# RSL15 register map
Vendor: ONSemiconductor; Series: RSL15 Series; File version: 1.0
CPU: CM33 r0p4, little endian, MPU, FPU, 3 interrupt priority bits
Registers are 32-bit, read-write, reset 0x0 unless marked. A register's access mark holds for its fields unless they carry their own. Offsets are from the block's base; [hi:lo] are bit positions; {n}, {i} and the like mark numbered series; <NAME> marks a mode.

## ACS
Base 0x40001B00
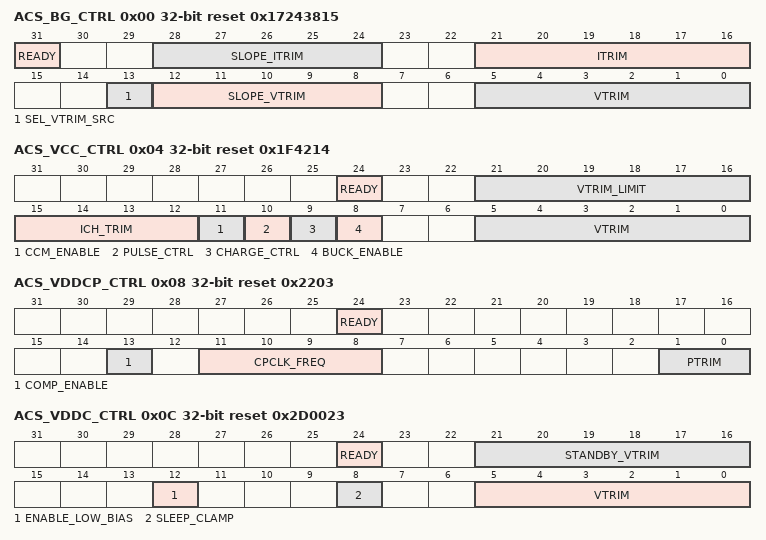
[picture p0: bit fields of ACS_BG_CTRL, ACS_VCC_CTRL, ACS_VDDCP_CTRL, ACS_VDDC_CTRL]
0x00 ACS_BG_CTRL reset 0x17243815 — Bandgap Control register
  [31] READY ro — Bandgap ready
    0=BG_NOT_READY (Bandgap reference not ready); 1=BG_READY (Bandgap reference ready)
  [28:24] SLOPE_ITRIM — Current temperature coefficient trimming
    23=BG_SLOPE_ITRIM_VALUE (Current temperature dependency 0 ppm/C)
  [21:16] ITRIM — Reference current trimming
    0=BG_ITRIM_0P64UA (0.64 uA); 1=BG_ITRIM_0P65UA (0.65 uA); 35=BG_ITRIM_0P99UA (0.99 uA); 36=BG_ITRIM_1P00UA (1.00 uA); 37=BG_ITRIM_1P01UA (1.01 uA); 62=BG_ITRIM_1P26UA (1.26 uA); 63=BG_ITRIM_1P27UA (1.27 uA)
  [13] SEL_VTRIM_SRC — Select trim source for SLOPE_VTRIM and VTRIM
    0=BG_VTRIM_SEL_REGISTER (Select register value); 1=BG_VTRIM_SEL_METAL (Select metal value)
  [12:8] SLOPE_VTRIM — Voltage temperature coefficient trimming
    24=BG_SLOPE_VTRIM_VALUE (Voltage temperature dependency 0 ppm/C)
  [5:0] VTRIM — Reference voltage trimming (5 mV steps)
    0=BG_VTRIM_MIN (bandgap voltage minimum trimming); 21=BG_VTRIM_DEFAULT (bandgap voltage default trimming); 63=BG_VTRIM_MAX (bandgap voltage maximum trimming)
0x04 ACS_VCC_CTRL reset 0x1F4214 — DC-DC / LDO Supply Configuration / Control register
  [24] READY ro — Supply ready (only makes sense in test mode)
    0=VCC_NOT_READY (Supply voltage not ready); 1=VCC_READY (Supply voltage ready)
  [21:16] VTRIM_LIMIT — Max VTRIM value that can be used. If VTRIM value is greater it will be limited to this value
    0=VCC_TRIM_LIMIT_1P00V (Output voltage limit 1.00V); 5=VCC_TRIM_LIMIT_1P05V (Output voltage limit 1.05V); 10=VCC_TRIM_LIMIT_1P10V (Output voltage limit 1.10V); 15=VCC_TRIM_LIMIT_1P15V (Output voltage limit 1.15V); 20=VCC_TRIM_LIMIT_1P20V (Output voltage limit 1.20V); 25=VCC_TRIM_LIMIT_1P25V (Output voltage limit 1.25V); 31=VCC_TRIM_LIMIT_1P31V (Output voltage limit 1.31V (This should be the max value allowed)); 35=VCC_TRIM_LIMIT_1P35V (Output voltage limit 1.35V (This is the max value allowed only during RF operation at max output power)); 63=VCC_TRIM_LIMIT_1P63V (Output voltage limit 1.63V)
  [15:12] ICH_TRIM — Inductor charge current trimming
    0=VCC_ICHTRIM_16MA (Charge pump max current to 16 mA); 1=VCC_ICHTRIM_32MA (Charge pump max current to 32 mA); 3=VCC_ICHTRIM_64MA (Charge pump max current to 64 mA); 4=VCC_ICHTRIM_80MA (Charge pump max current to 80 mA); 5=VCC_ICHTRIM_96MA (Charge pump max current to 96 mA); 15=VCC_ICHTRIM_256MA (Charge pump max current to 256 mA)
  [11] CCM_ENABLE — Enable CCM mode
    0=VCC_DCM_MODE (Discontinous current mode); 1=VCC_CCM_MODE (Continuous current mode enabled)
  [10] PULSE_CTRL — Pulse mode control
    0=VCC_SINGLE_PULSE (Single pulse per clock cycle); 1=VCC_MULTI_PULSE (Multi pulses enabled (until VCC > VCC_TRIM))
  [9] CHARGE_CTRL — Charge mode control
    0=VCC_CONSTANT_CHARGE (Constant charge transfer (valid for VBAT > VCC+0.2)); 1=VCC_CONSTANT_IMAX (Constant inductor maximum charge current)
  [8] BUCK_ENABLE — Enable buck converter mode
    0=VCC_LDO (Linear mode); 1=VCC_BUCK (Buck converter mode enabled)
  [5:0] VTRIM — Output voltage trimming configuration in 10 mV steps
    0=VCC_TRIM_1P00V (Output voltage 1.00V); 5=VCC_TRIM_1P05V (Output voltage 1.05V); 10=VCC_TRIM_1P10V (Output voltage 1.10V); 15=VCC_TRIM_1P15V (Output voltage 1.15V); 20=VCC_TRIM_1P20V (Output voltage 1.20V); 25=VCC_TRIM_1P25V (Output voltage 1.25V); 31=VCC_TRIM_1P31V (Output voltage 1.31V (This should be the max value allowed)); 35=VCC_TRIM_1P35V (Output voltage 1.35V (This is the absolute max value allowed, only for RF operation at max output power)); 63=VCC_TRIM_1P63V (Output voltage 1.63V)
0x08 ACS_VDDCP_CTRL reset 0x2203 — Charge Pump control register
  [24] READY ro — Supply ready
    0=VDDCP_NOT_READY (Charge pump voltage not ready); 1=VDDCP_READY (Charge pump voltage ready)
  [13] COMP_ENABLE — Force cp comparator enable
    0=VDDCP_COMP_AUTO (Comparator and resistive divider turned off when not required); 1=VDDCP_COMP_ENABLED (Comparator and resistive divider turned on (retro-compatible))
  [11:8] CPCLK_FREQ — Charge Pump clock frequency during power down modes
    0=VDDCP_CPCLK_32KHZ (CP clock = 32 kHz (WDG_SoC clock)); 1=VDDCP_CPCLK_16KHZ (CP clock = 16 kHz); 2=VDDCP_CPCLK_8KHZ (CP clock = 8 kHz); 3=VDDCP_CPCLK_4KHZ (CP clock = 4 kHz); 4=VDDCP_CPCLK_2KHZ (CP clock = 2 kHz); 5=VDDCP_CPCLK_1KHZ (CP clock = 1 kHz); 6=VDDCP_CPCLK_0P5KHZ (CP clock = 512 Hz); 7=VDDCP_CPCLK_0P25KHZ (CP clock = 256 Hz); 8=VDDCP_CPCLK_0P12KHZ (CP clock = 128 Hz)
  [1:0] PTRIM — Output power trimming
    0=VDDCP_PTRIM_4MA (CP max current to 4 mA); 1=VDDCP_PTRIM_8MA (CP max current to 8 mA); 2=VDDCP_PTRIM_12MA (CP max current to 12 mA); 3=VDDCP_PTRIM_16MA (CP max current to 16 mA)
0x0C ACS_VDDC_CTRL reset 0x2D0023 — Digital Core Voltage Regulator control register
  [24] READY ro — Supply ready
    0=VDDC_NOT_READY (Supply voltage not ready); 1=VDDC_READY (Supply voltage ready)
  [21:16] STANDBY_VTRIM — VDDC standby voltage trimming (10 mV steps)
    0=VDDC_STANDBY_TRIM_0P75V (0.75 V); 1=VDDC_STANDBY_TRIM_0P76V (0.76 V); 45=VDDC_STANDBY_TRIM_1P20V (1.2 V); 57=VDDC_STANDBY_TRIM_1P32V (1.32 V); 63=VDDC_STANDBY_TRIM_1P38V (1.38 V)
  [12] ENABLE_LOW_BIAS — Low power mode control
    0=VDDC_NOMINAL_BIAS (Nominal regulator biasing); 1=VDDC_LOW_BIAS (Low regulator biasing)
  [8] SLEEP_CLAMP — Sleep mode clamp control
    0=VDDC_SLEEP_HIZ (Set the output HIZ (floating) in sleep mode); 1=VDDC_SLEEP_GND (Clamp output to ground in sleep mode)
  [5:0] VTRIM — Output voltage trimming configuration in 10 mV steps
    0=VDDC_TRIM_0P75V (0.75 V); 1=VDDC_TRIM_0P76V (0.76 V); 25=VDDC_TRIM_1P00V (1.0 V); 33=VDDC_TRIM_1P08V (1.08 V); 35=VDDC_TRIM_1P10V (1.1 V); 45=VDDC_TRIM_1P20V (1.2 V); 50=VDDC_TRIM_1P25V (1.25 V); 57=VDDC_TRIM_1P32V (1.32 V); 63=VDDC_TRIM_1P38V (1.38 V)
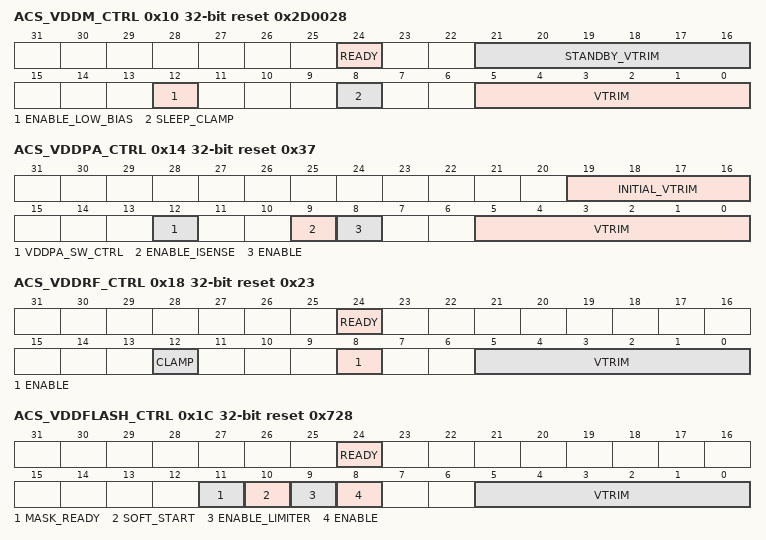
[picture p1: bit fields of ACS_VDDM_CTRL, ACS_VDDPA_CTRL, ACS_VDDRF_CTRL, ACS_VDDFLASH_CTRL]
0x10 ACS_VDDM_CTRL reset 0x2D0028 — Digital Core Voltage Regulator control register
  [24] READY ro — Supply ready
    0=VDDM_NOT_READY (Supply voltage not ready); 1=VDDM_READY (Supply voltage ready)
  [21:16] STANDBY_VTRIM — VDDM standby voltage trimming (10 mV steps)
    0=VDDM_STANDBY_TRIM_0P75V (0.75 V); 1=VDDM_STANDBY_TRIM_0P76V (0.76 V); 45=VDDM_STANDBY_TRIM_1P20V (1.2 V); 57=VDDM_STANDBY_TRIM_1P32V (1.32 V); 63=VDDM_STANDBY_TRIM_1P38V (1.38 V)
  [12] ENABLE_LOW_BIAS — Low power mode control
    0=VDDM_NOMINAL_BIAS (Nominal regulator biasing); 1=VDDM_LOW_BIAS (Low regulator biasing)
  [8] SLEEP_CLAMP — Sleep mode clamp control
    0=VDDM_SLEEP_HIZ (Set the output HIZ (floating) in sleep mode); 1=VDDM_SLEEP_GND (Clamp output to ground in sleep mode)
  [5:0] VTRIM — Output voltage trimming configuration in 10 mV steps
    0=VDDM_TRIM_0P75V (0.75 V); 1=VDDM_TRIM_0P76V (0.76 V); 25=VDDM_TRIM_1P00V (1.0 V); 33=VDDM_TRIM_1P08V (1.08 V); 35=VDDM_TRIM_1P10V (1.1 V); 40=VDDM_TRIM_1P15V (1.15 V); 45=VDDM_TRIM_1P20V (1.2 V); 50=VDDM_TRIM_1P25V (1.25 V); 57=VDDM_TRIM_1P32V (1.32 V); 63=VDDM_TRIM_1P38V (1.38 V)
0x14 ACS_VDDPA_CTRL reset 0x37 — RF Block Regulator Configuration / Control register
  [19:16] INITIAL_VTRIM — Initial output voltage trimming configuration in 10 mV steps
    0=VDDPA_INITIAL_TRIM_1P05V (1.05 V); 5=VDDPA_INITIAL_TRIM_1P10V (1.10 V); 15=VDDPA_INITIAL_TRIM_1P20V (1.20 V)
  [12] VDDPA_SW_CTRL — Power amplifier supply control
    0=VDDPA_SW_HIZ (Set the output HIZ (floating) in disable mode); 1=VDDPA_SW_VDDRF (Connect switched output to VDDRF regulator (ENABLE bit must be reset))
  [9] ENABLE_ISENSE — Enable current sensing circuit
    0=VDDPA_ISENSE_DISABLE (Disable the VDDPA regulator current sensing circuit); 1=VDDPA_ISENSE_ENABLE (Enable the VDDPA regulator current sensing circuit)
  [8] ENABLE — Enable control
    0=VDDPA_DISABLE (Disable the VDDPA regulator); 1=VDDPA_ENABLE (Enable the VDDPA regulator)
  [5:0] VTRIM — Output voltage trimming configuration in 10 mV steps
    0=VDDPA_TRIM_1P05V (1.05 V); 1=VDDPA_TRIM_1P06V (1.06 V); 54=VDDPA_TRIM_1P59V (1.59 V); 55=VDDPA_TRIM_1P60V (1.60 V); 56=VDDPA_TRIM_1P61V (1.61 V); 63=VDDPA_TRIM_1P68V (1.68 V)
0x18 ACS_VDDRF_CTRL reset 0x23 — RF Regulator control register
  [24] READY ro — Supply ready
    0=VDDRF_NOT_READY (Supply voltage not ready); 1=VDDRF_READY (Supply voltage ready)
  [12] CLAMP — Disable mode clamp control
    0=VDDRF_DISABLE_HIZ (Set the output HIZ (floating) in disable mode); 1=VDDRF_DISABLE_GND (Clamp output to ground in disable mode)
  [8] ENABLE — Enable control
    0=VDDRF_DISABLE (Disable the VDDRF regulator); 1=VDDRF_ENABLE (Enable the VDDRF regulator)
  [5:0] VTRIM — Output voltage trimming configuration in 10 mV steps
    0=VDDRF_TRIM_0P75V (0.75 V); 1=VDDRF_TRIM_0P76V (0.76 V); 25=VDDRF_TRIM_1P00V (1.0 V); 33=VDDRF_TRIM_1P08V (1.08 V); 35=VDDRF_TRIM_1P10V (1.1 V); 45=VDDRF_TRIM_1P20V (1.2 V); 57=VDDRF_TRIM_1P32V (1.32 V); 63=VDDRF_TRIM_1P38V (1.38 V)
0x1C ACS_VDDFLASH_CTRL reset 0x728 — VDDFLASH Block Regulator Configuration / Control register
  [24] READY ro — Supply ready
    0=VDDFLASH_NOT_READY (Supply voltage not ready); 1=VDDFLASH_READY (Supply voltage ready)
  [11] MASK_READY — Apply a mask to reset logic to ignore VDDFLASH ready signal
    0=VDDFLASH_USE_READY (Reset logic use VDDFLASH ready); 1=VDDFLASH_MASK_READY (Reset ignore VDDFLASH ready)
  [10] SOFT_START — Current limiter threshold setting
    0=VDDFLASH_LIMITER_70MA (Limiter current threshold at 70mA); 1=VDDFLASH_LIMITER_4MA (Limiter current threshold at 4mA)
  [9] ENABLE_LIMITER — Enable current limiter circuit
    0=VDDFLASH_LIMITER_DISABLE (Disable the VDDFLASH regulator current limiter circuit); 1=VDDFLASH_LIMITER_ENABLE (Enable the VDDFLASH regulator current limiter circuit)
  [8] ENABLE — Enable control
    0=VDDFLASH_DISABLE (Disable the VDDFLASH regulator); 1=VDDFLASH_ENABLE (Enable the VDDFLASH regulator)
  [5:0] VTRIM — Output voltage trimming configuration in 25 mV steps
    0=VDDFLASH_TRIM_0P750V (0.750V); 1=VDDFLASH_TRIM_0P775V (0.775V); 39=VDDFLASH_TRIM_1P725V (1.725V); 40=VDDFLASH_TRIM_1P750V (1.750V); 41=VDDFLASH_TRIM_1P775V (1.775V); 62=VDDFLASH_TRIM_2P300V (2.300V); 63=VDDFLASH_TRIM_2P325V (2.325V)
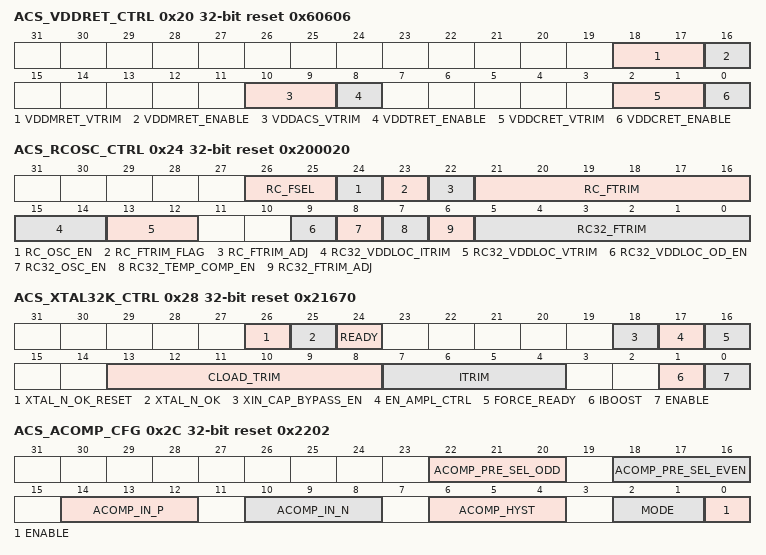
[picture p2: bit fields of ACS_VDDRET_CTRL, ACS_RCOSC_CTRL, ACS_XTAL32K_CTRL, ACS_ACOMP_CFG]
0x20 ACS_VDDRET_CTRL reset 0x60606 — Retention Regulator control register
  [18:17] VDDMRET_VTRIM — VDDMRET retention regulator voltage trimming
    3=VDDMRET_TRIM_VALUE (VDDMRET trimming value)
  [16] VDDMRET_ENABLE — Enable/Disable the VDDMRET retention regulator
    0=VDDMRET_DISABLE (The VDDMRET retention regulator is disabled); 1=VDDMRET_ENABLE (The VDDMRET retention regulator is enabled)
  [10:9] VDDACS_VTRIM — VDDACS regulator voltage trimming
    3=VDDACS_TRIM_VALUE (VDDACS trimming value)
  [8] VDDTRET_ENABLE — Enables the VDDT retention power (activate switch from VDDACS)
    0=VDDTRET_DISABLE (Disable BB timer retention supply (VDDT)); 1=VDDTRET_ENABLE (Enable BB timer retention supply (VDDT))
  [2:1] VDDCRET_VTRIM — VDDCRET Retention regulator voltage trimming
    3=VDDCRET_TRIM_VALUE (VDDCRET trimming value)
  [0] VDDCRET_ENABLE — Enables the VDDCRET Retention regulator
    0=VDDCRET_DISABLE (The VDDCRET retention regulator is disabled); 1=VDDCRET_ENABLE (The VDDCRET retention regulator is enabled)
0x24 ACS_RCOSC_CTRL reset 0x200020 — RC Oscillator control register
  [26:25] RC_FSEL — Select RC oscillator frequency
    0=RC_OSC_3MHZ (The RC Oscillator is at 3 MHz); 1=RC_OSC_12MHZ (The RC Oscillator is at 12 MHz); 2=RC_OSC_24MHZ (The RC Oscillator is at 24 MHz)
  [24] RC_OSC_EN — Enable/Disable the RC Oscillator
    0=RC_OSC_AUTO (The RC Oscillator is in auto mode); 1=RC_OSC_ENABLE (The RC Oscillator is enabled)
  [23] RC_FTRIM_FLAG — RC Oscillator Trimming flag
    0=RC_OSC_UNCALIBRATED (The oscillators are not calibrated); 1=RC_OSC_CALIBRATED (The oscillators are calibrated)
  [22] RC_FTRIM_ADJ — Adjust RC oscillator frequency range
    0=RC_OSC_RANGE_NOM (The RC Oscillator frequency range is nominal); 1=RC_OSC_RANGE_M15 (The RC Osc higher trim freq is decreased by 15 percent)
  [21:16] RC_FTRIM — RC oscillator frequency trimming
    0=RC_OSC_M48 (-48 percent trimming); 1=RC_OSC_M46P5 (-46.5 percent trimming); 32=RC_OSC_NOM (Nominal frequency); 63=RC_OSC_P46P5 (+46.5 percent trimming)
  [15:14] RC32_VDDLOC_ITRIM — VDDLOC current trimming
  [13:12] RC32_VDDLOC_VTRIM — VDDLOC voltage trimming
  [9] RC32_VDDLOC_OD_EN — Enable the overdrive of vddloc with VBAT
    0=RC32_OSC_VDDLOC_OD_DISABLE; 1=RC32_OSC_VDDLOC_OD_ENABLE
  [8] RC32_OSC_EN — Enable/Disable the 32 kHz RC Oscillator
    0=RC32_OSC_DISABLE (The 32kHz RC Oscillator is disabled); 1=RC32_OSC_ENABLE (The 32kHz RC Oscillator is enabled)
  [7] RC32_TEMP_COMP_EN — Enable/Disable the 32 kHz RC Oscillator
    0=RC32_TEMP_COMP_DISABLE (The 32kHz RC Oscillator temperature compensation is disabled); 1=RC32_TEMP_COMP_ENABLE (The 32kHz RC Oscillator temperature compensation is enabled)
  [6] RC32_FTRIM_ADJ — Adjust 32 kHz RC oscillator frequency range
    0=RC32_OSC_RANGE_NOM (The 32 kHz RC Oscillator frequency range is nominal); 1=RC32_OSC_RANGE_M25 (The 32 kHz RC Oscillator frequency range is lowered by 25 percent)
  [5:0] RC32_FTRIM — 32 kHz RC oscillator frequency trimming
    0=RC32_OSC_M48 (-48 percent trimming); 1=RC32_OSC_M46P5 (-46.5 percent trimming); 32=RC32_OSC_NOM (Nominal frequency); 63=RC32_OSC_P46P5 (+46.5 percent trimming)
0x28 ACS_XTAL32K_CTRL reset 0x21670 (reset mask 0x3073FF3) — Xtal 32 kHz configuration register
  [26] XTAL_N_OK_RESET wo — Reset Xtal not ok sticky flag
    1=XTAL32K_NOT_OK_RESET (Xtal 32K not reset)
  [25] XTAL_N_OK ro — Xtal not ready sticky flag
    0=XTAL_OK (Xtal 32K NOT OK sticky flag was not set); 1=XTAL_N_OK (Xtal 32K NOT OK sticky flag was set)
  [24] READY ro — Xtal ready status
    0=XTAL32K_NOT_OK (Xtal 32K not available); 1=XTAL32K_OK (Xtal 32K is OK)
  [18] XIN_CAP_BYPASS_EN — Switch to bypass the added XIN serial cap to reduce the leakage
    0=XTAL32K_XIN_CAP_BYPASS_DISABLE (Disable the Xtal bypass switch of the XIN serial cap); 1=XTAL32K_XIN_CAP_BYPASS_ENABLE (Enable the Xtal bypass switch of the XIN serial cap)
  [17] EN_AMPL_CTRL — Xtal enable amplitude control (regulation)
    0=XTAL32K_AMPL_CTRL_DISABLE (Xtal 32K amplitude control disabled); 1=XTAL32K_AMPL_CTRL_ENABLE (Xtal 32K amplitude control enabled)
  [16] FORCE_READY — Xtal bypass the ready detector
    0=XTAL32K_NOT_FORCE_READY (Xtal 32K ready not forced); 1=XTAL32K_FORCE_READY (Xtal 32K ready forced)
  [13:8] CLOAD_TRIM — Xtal load capacitance configuration
    0=XTAL32K_CTRIM_0P0PF (0 pF internal capacitor); 1=XTAL32K_CTRIM_0P4PF (0.4 pF internal capacitor); 22=XTAL32K_CTRIM_8P8PF (8.8 pF internal capacitor); 63=XTAL32K_CTRIM_25P2PF (25.2 pF internal capacitor)
  [7:4] ITRIM — Xtal current trimming
    0=XTAL32K_ITRIM_20NA (20 nA startup current); 3=XTAL32K_ITRIM_80NA (80 nA startup current); 7=XTAL32K_ITRIM_160NA (160 nA startup current); 15=XTAL32K_ITRIM_320NA (320 nA startup current)
  [1] IBOOST — Xtal current boosting (4x)
    0=XTAL32K_IBOOST_DISABLE (Disable the Xtal 32 kHz current boosting mode); 1=XTAL32K_IBOOST_ENABLE (Disable the Xtal 32 kHz enable boosting mode (4x itrim currents))
  [0] ENABLE — Enable the Xtal 32 kHz oscillator
    0=XTAL32K_DISABLE (Disable the Xtal 32 kHz oscillator); 1=XTAL32K_ENABLE (Enable the Xtal 32 kHz oscillator)
0x2C ACS_ACOMP_CFG reset 0x2202 — ACOMP configuration register
  [22:20] ACOMP_PRE_SEL_ODD — Pre selection of odd GPIOs
    0=ACOMP_PRE_SEL_GPIO_1 (Select GPIO[1] for "pre_sel_odd"); 1=ACOMP_PRE_SEL_GPIO_3 (Select GPIO[3] for "pre_sel_odd"); 2=ACOMP_PRE_SEL_GPIO_5 (Select GPIO[5] for "pre_sel_odd"); 3=ACOMP_PRE_SEL_GPIO_7 (Select GPIO[7] for "pre_sel_odd"); 4=ACOMP_PRE_SEL_GPIO_9 (Select GPIO[9] for "pre_sel_odd"); 5=ACOMP_PRE_SEL_GPIO_11 (Select GPIO[11] for "pre_sel_odd"); 6=ACOMP_PRE_SEL_GPIO_13 (Select GPIO[13] for "pre_sel_odd"); 7=ACOMP_PRE_SEL_GPIO_15 (Select GPIO[15] for "pre_sel_odd")
  [18:16] ACOMP_PRE_SEL_EVEN — Pre selection of even GPIOs
    0=ACOMP_PRE_SEL_GPIO_0 (Select GPIO[0] for "pre_sel_even"); 1=ACOMP_PRE_SEL_GPIO_2 (Select GPIO[2] for "pre_sel_even"); 2=ACOMP_PRE_SEL_GPIO_4 (Select GPIO[4] for "pre_sel_even"); 3=ACOMP_PRE_SEL_GPIO_6 (Select GPIO[6] for "pre_sel_even"); 4=ACOMP_PRE_SEL_GPIO_8 (Select GPIO[8] for "pre_sel_even"); 5=ACOMP_PRE_SEL_GPIO_10 (Select GPIO[10] for "pre_sel_even"); 6=ACOMP_PRE_SEL_GPIO_12 (Select GPIO[12] for "pre_sel_even"); 7=ACOMP_PRE_SEL_GPIO_14 (Select GPIO[14] for "pre_sel_even")
  [14:12] ACOMP_IN_P — Defines the positive input signal
    0=ACOMP_IN_P_SRC_PRE_SEL_EVEN (Select "pre_sel_even" as source); 1=ACOMP_IN_P_SRC_PRE_SEL_ODD (Select "pre_sel_odd" as source); 2=ACOMP_IN_P_SRC_VSSA (Select VSSA as source); 3=ACOMP_IN_P_SRC_WEDAC (Select WEDAC as source); 4=ACOMP_IN_P_SRC_PMU_VREF (Select PMU Vref as source); 5=ACOMP_IN_P_SRC_VBAT (Select VBAT as source); 6=ACOMP_IN_P_SRC_NOT_CONNECTED (Not connect the source)
  [10:8] ACOMP_IN_N — Defines the negative input signal
    0=ACOMP_IN_N_SRC_PRE_SEL_EVEN (Select "pre_sel_even" as source); 1=ACOMP_IN_N_SRC_PRE_SEL_ODD (Select "pre_sel_odd" as source); 2=ACOMP_IN_N_SRC_VSSA (Select VSSA as source); 3=ACOMP_IN_N_SRC_WEDAC (Select WEDAC as source); 4=ACOMP_IN_N_SRC_PMU_VREF (Select PMU Vref as source); 5=ACOMP_IN_N_SRC_VBAT (Select VBAT as source); 6=ACOMP_IN_N_SRC_NOT_CONNECTED (Not connect the source)
  [6:4] ACOMP_HYST — Hysteresis level
    0=HYST_0 (No hysteresis); 1=HYST_10MV (10 mV hysteresis); 2=HYST_20MV (20 mV hysteresis); 3=HYST_30MV (30 mV hysteresis); 4=HYST_40MV (40 mV hysteresis); 5=HYST_50MV (50 mV hysteresis); 6=HYST_60MV (60 mV hysteresis); 7=HYST_70MV (70 mV hysteresis)
  [2:1] MODE — Power mode selection
    0=ACOMP_LOW_POWER_MODE (Low power mode); 1=ACOMP_NORMAL_MODE (Normal mode); 2=ACOMP_HIGH_SPEED_MODE (High Speed mode)
  [0] ENABLE — Enable signal
    0=ACOMP_DIS (ACOMP disabled); 1=ACOMP_EN (ACOMP enabled)
0x30 ACS_ACOMP_OUT ro — ACOMP out
  [0] ACOMP_OUT — Comparison result
    0=Vinn > Vinp; 1=Vinn < Vinp
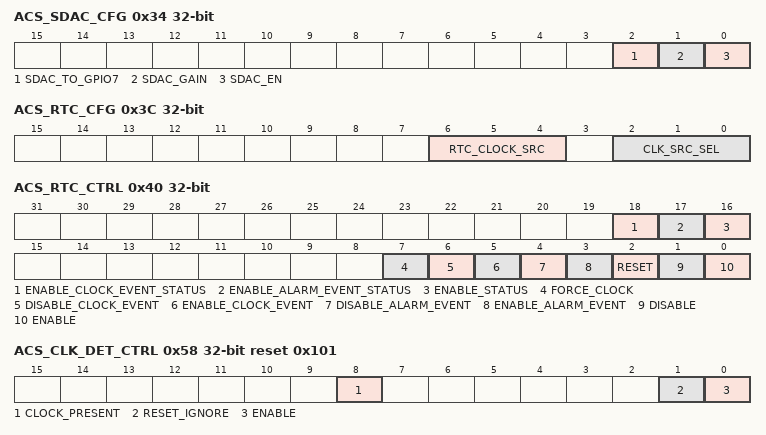
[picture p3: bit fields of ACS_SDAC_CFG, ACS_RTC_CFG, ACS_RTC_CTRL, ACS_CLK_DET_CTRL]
0x34 ACS_SDAC_CFG — SDAC configuration register
  [2] SDAC_TO_GPIO7 — GPIO7 drive by SDAC
    0=GPIO7_NOT_DRIVE_BY_SDAC (GPIO[7] not driven by SDAC); 1=GPIO7_DRIVE_BY_SDAC (GPIO[7] drives by SDAC)
  [1] SDAC_GAIN — Sets the SDAC buffer gain
    0=SDAC_GAIN_X1 (Gain = 1); 1=SDAC_GAIN_X2 (Gain = 2)
  [0] SDAC_EN — Enable signal for SDAC buffer
    0=SDAC_DISABLE (SDAC disabled); 1=SDAC_ENABLE (SDAC enabled)
0x38 ACS_WEDAC_CTRL reset 0x26 — WEDAC Control register
  [5:0] WEDAC — WEDAC setting
    0=WEDAC_0P000V (WEDAC = 0.000V); 1=WEDAC_0P016V (WEDAC = 0.016V); 2=WEDAC_0P032V (WEDAC = 0.032V); 31=WEDAC_0P496V (WEDAC = 0.496V); 32=WEDAC_0P504V (WEDAC = 0.504V); 38=WEDAC_0P600V (WEDAC = 0.600V); 39=WEDAC_0P616V (WEDAC = 0.616V); 62=WEDAC_0P984V (WEDAC = 0.984V); 63=WEDAC_1P000V (WEDAC = 1.000V)
0x3C ACS_RTC_CFG — RTC Configuration Register
  [6:4] RTC_CLOCK_SRC — Select the RTC Clock event source
    0=RTC_CLOCK_62MS (RTC clock on counter bit 10 rising edge (62 ms)); 1=RTC_CLOCK_125MS (RTC clock on counter bit 11 rising edge (125 ms)); 2=RTC_CLOCK_250MS (RTC clock on counter bit 12 rising edge (250 ms)); 3=RTC_CLOCK_500MS (RTC clock on counter bit 13 rising edge (500 ms)); 4=RTC_CLOCK_1S (RTC clock on counter bit 14 rising edge (1 s)); 5=RTC_CLOCK_2S (RTC clock on counter bit 15 rising edge (2 s)); 6=RTC_CLOCK_4S (RTC clock on counter bit 16 rising edge (4 s)); 7=RTC_CLOCK_8S (RTC clock on counter bit 17 rising edge (8 s))
  [2:0] CLK_SRC_SEL — Select the RTC, standby, bb timer, and sensor block clock source
    0=RTC_CLK_SRC_STANDBY_CLK (Select standby clock that runs at 32kHz as clock source); {v}=RTC_CLK_SRC_GPIO{v-1} (Select GPIO[{v-1}] as clock source) (v=1..4); 5=RTC_CLK_SRC_NO_CLOCK (Set RTC clock to constant value 0)
0x40 ACS_RTC_CTRL (reset mask 0x70000) — RTC Control Register
  [18] ENABLE_CLOCK_EVENT_STATUS ro — Status of the RTC clock event enable
    0=RTC_CLOCK_EVENT_IS_DISABLED (The RTC clock event is disabled); 1=RTC_CLOCK_EVENT_IS_ENABLED (The RTC clock event is enabled)
  [17] ENABLE_ALARM_EVENT_STATUS ro — Status of the RTC alarm event enable
    0=RTC_ALARM_EVENT_IS_DISABLED (The RTC alarm event is disabled); 1=RTC_ALARM_EVENT_IS_ENABLED (The RTC alarm event is enabled)
  [16] ENABLE_STATUS ro — Status of the RTC enable
    0=RTC_IS_DISABLED (The RTC is disabled); 1=RTC_IS_ENABLED (The RTC is enabled)
  [7] FORCE_CLOCK wo — Force a clock on RTC timer (Test Purpose)
    1=RTC_FORCE_CLOCK (Clock the RTC timer (has an effect only if the source clock is low))
  [6] DISABLE_CLOCK_EVENT wo — Disable clock event and its interrupt
    1=RTC_DISABLE_CLOCK_EVENT (Disable RTC clock event)
  [5] ENABLE_CLOCK_EVENT wo — Enable clock event and its interrupt
    1=RTC_ENABLE_CLOCK_EVENT (Enable RTC clock event)
  [4] DISABLE_ALARM_EVENT wo — Disable alarm event and its interrupt
    1=RTC_DISABLE_ALARM_EVENT (Disable RTC alarm event)
  [3] ENABLE_ALARM_EVENT wo — Enable alarm event and its interrupt
    1=RTC_ENABLE_ALARM_EVENT (Enable RTC alarm event)
  [2] RESET wo — Reset the RTC timer
    1=RTC_RESET (The RTC counters are reset (prescale and counter))
  [1] DISABLE wo — Disable counter and RTC interrupt every 1s
    1=RTC_DISABLE (Disable RTC)
  [0] ENABLE wo — Enable counter and RTC interrupt every 1s
    1=RTC_ENABLE (Enable RTC)
0x44 ACS_RTC_COUNT_THRES reset 0xFFFFFFFF — RTC Counter Threshold
  [31:0] THRESHOLD — Compare value for the RTC counter
    0=RTC_COUNT_THRES_0 (Compare to 0); 1=RTC_COUNT_THRES_1 (Compare to 1); 0x7FFF=RTC_COUNT_THRES_32767 (Compare to 32,767); 0xFFFFFFFF=RTC_COUNT_THRES_4294967295 (Compare to 4,294,967,295)
0x48 ACS_RTC_COUNT ro — RTC Counter Current Value
  [31:0] VALUE — RTC timer current value
0x4C ACS_RTC_SECONDS ro — RTC Counter Current Value in seconds
  [16:0] VALUE — RTC timer current value in seconds
0x50 ACS_RTC_COUNT_LOAD reset not defined — Load RTC Counter Current Value
  [31:0] VALUE wo — Load the RTC timer current value
0x54 ACS_BB_TIMER_CTRL — Baseband timer and standby clock control register
  [0] BB_TIMER_NRESET — nReset signal for the baseband timer
    0=BB_TIMER_RESET (Baseband timer is in reset state); 1=BB_TIMER_NRESET (Baseband timer reset is released)
0x58 ACS_CLK_DET_CTRL reset 0x101 — Clock Detector Configuration register
  [8] CLOCK_PRESENT ro — Clock present flag
    0=ACS_CLK_DET_NO_CLOCK (No clock detected); 1=ACS_CLK_DET_CLOCK_PRESENT (Clock detected)
  [1] RESET_IGNORE — Clock detector reset condition ignore
    1=ACS_CLK_DET_RESET_DISABLE (Clock detector reset condition ignore); 0=ACS_CLK_DET_RESET_ENABLE (Clock detector reset condition accept)
  [0] ENABLE — Clock detector enable
    1=ACS_CLK_DET_ENABLE (Clock detector enable); 0=ACS_CLK_DET_DISABLE (Clock detector disable)
0x5C ACS_PWR_MODES_CTRL reset not defined — Power Modes Control Register
  [31:0] POWER_MODE wo — 32-bit key to enter STANDBY, SLEEP, or DEEP_SLEEP mode. This register must be written using a 32-bit access.
    0=PWR_RUN_MODE (Keep the system in normal RUN mode); 0x9B1D79A0=PWR_STANDBY_MODE (Enter STANDBY mode); 0xE0045650=PWR_SLEEP_MODE (Enter SLEEP mode); 0x53C02890=PWR_DEEP_SLEEP_MODE (Enter DEEP_SLEEP mode)
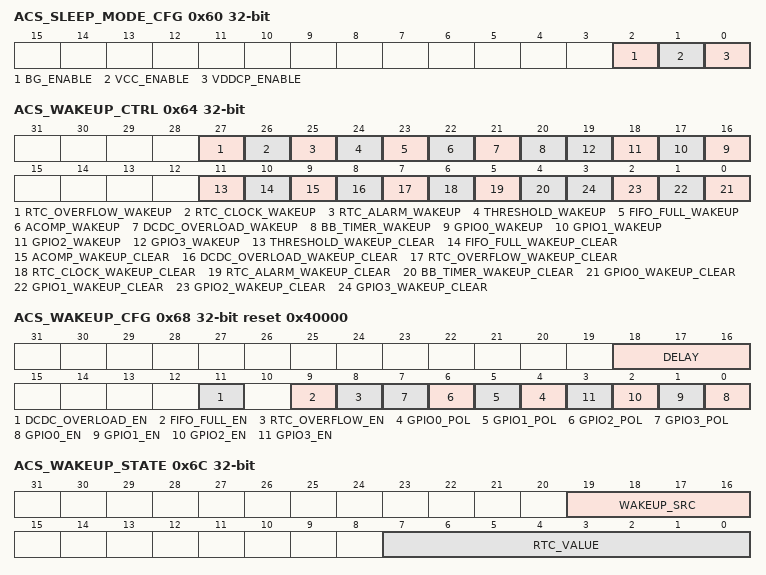
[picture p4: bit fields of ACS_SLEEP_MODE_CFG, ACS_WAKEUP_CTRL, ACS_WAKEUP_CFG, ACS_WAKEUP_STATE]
0x60 ACS_SLEEP_MODE_CFG — Sleep power mode configuration
  [2] BG_ENABLE — Keep Band-gap enabled during sleep
    0=BG_DISABLE_IN_SLEEP (Band-gap disabled in sleep); 1=BG_ENABLE_IN_SLEEP (Band-gap enabled in sleep)
  [1] VCC_ENABLE — Keep VCC low power enabled during sleep
    0=VCC_DISABLE_IN_SLEEP (VCC disabled in sleep); 1=VCC_ENABLE_IN_SLEEP (VCC enabled in sleep)
  [0] VDDCP_ENABLE — Keep VDDCP charge pump enabled during sleep
    0=VDDCP_DISABLE_IN_SLEEP (Charge pump disabled in sleep); 1=VDDCP_ENABLE_IN_SLEEP (Charge pump enabled in sleep)
0x64 ACS_WAKEUP_CTRL (reset mask 0xFFF0000) — Wake-Up control / Status Register
  [27] RTC_OVERFLOW_WAKEUP ro — Indicate if RTC overflow has triggered a wake-up event
    0=WAKEUP_RTC_OVERFLOW_EVENT_NOT_SET (RTC overflow has not triggered a wake-up event); 1=WAKEUP_RTC_OVERFLOW_EVENT_SET (RTC overflow has triggered a wake-up event at least once)
  [26] RTC_CLOCK_WAKEUP ro — Indicate if RTC clock has triggered a wake-up event
    0=WAKEUP_RTC_CLOCK_EVENT_NOT_SET (RTC clock has not triggered a wake-up event); 1=WAKEUP_RTC_CLOCK_EVENT_SET (RTC clock has triggered a wake-up event at least once)
  [25] RTC_ALARM_WAKEUP ro — Indicate if RTC alarm has triggered a wake-up event
    0=WAKEUP_RTC_ALARM_EVENT_NOT_SET (RTC alarm has not triggered a wake-up event); 1=WAKEUP_RTC_ALARM_EVENT_SET (RTC alarm has triggered a wake-up event at least once)
  [24] THRESHOLD_WAKEUP ro — Indicate if the sensor interface threshold has triggered a wake-up event
    0=WAKEUP_THRESHOLD_EVENT_NOT_SET (The ULP data acquisition subsystem threshold has not triggered a wake-up event); 1=WAKEUP_THRESHOLD_EVENT_SET (The ULP data acquisition subsystem threshold has triggered a wake-up event at least once)
  [23] FIFO_FULL_WAKEUP ro — Indicate if the sensor interface FIFO has triggered a wake-up event
    0=WAKEUP_FIFO_FULL_EVENT_NOT_SET (The ULP data acquisition subsystem FIFO has not triggered a wake-up event); 1=WAKEUP_FIFO_FULL_EVENT_SET (The ULP data acquisition subsystem FIFO has triggered a wake-up event at least once)
  [22] ACOMP_WAKEUP ro — Indicate if ACOMP has triggered a wake-up event
    0=WAKEUP_ACOMP_EVENT_NOT_SET (The ACOMP has not triggered a wake-up event); 1=WAKEUP_ACOMP_EVENT_SET (The ACOMP has triggered a wake-up event at least once)
  [21] DCDC_OVERLOAD_WAKEUP ro — Indicate if DCDC overload has triggered a wake-up event
    0=WAKEUP_DCDC_OVERLOAD_EVENT_NOT_SET (DCDC overload has not triggered a wake-up event); 1=WAKEUP_DCDC_OVERLOAD_EVENT_SET (DCDC overload has triggered a wake-up event at least once)
  [20] BB_TIMER_WAKEUP ro — Indicate if baseband timer has triggered a wake-up event
    0=WAKEUP_BB_TIMER_EVENT_NOT_SET (BB timer has not triggered a wake-up event); 1=WAKEUP_BB_TIMER_EVENT_SET (BB timer has triggered a wake-up event at least once)
  [n+16] GPIO{n}_WAKEUP ro (n=0..3) — Indicate if GPIO{n} has triggered a wake-up event
    0=WAKEUP_GPIO{n}_EVENT_NOT_SET (GPIO{n} has not triggered a wake-up event); 1=WAKEUP_GPIO{n}_EVENT_SET (GPIO{n} has triggered a wake-up event at least once)
  [11] THRESHOLD_WAKEUP_CLEAR wo — Reset the sticky WAKEUP_THRESHOLD_EVENT flag
    1=THRESHOLD_FULL_EVENT_CLEAR (Reset the sticky WAKEUP_THRESHOLD_EVENT flag)
  [10] FIFO_FULL_WAKEUP_CLEAR wo — Reset the sticky WAKEUP_FIFO_FULL_EVENT flag
    1=WAKEUP_FIFO_FULL_EVENT_CLEAR (Reset the sticky WAKEUP_FIFO_FULL_EVENT flag)
  [9] ACOMP_WAKEUP_CLEAR wo — Reset the sticky WAKEUP_ACOMP_EVENT flag
    1=WAKEUP_ACOMP_EVENT_CLEAR (Reset the sticky WAKEUP_ACOMP_EVENT flag)
  [8] DCDC_OVERLOAD_WAKEUP_CLEAR wo — Reset the sticky WAKEUP_DCDC_OVERLOAD flag
    1=WAKEUP_DCDC_OVERLOAD_EVENT_CLEAR (Reset the sticky WAKEUP_DCDC_OVERLOAD flag)
  [7] RTC_OVERFLOW_WAKEUP_CLEAR wo — Reset the sticky WAKEUP_RTC_OVERFLOW_EVENT flag
    1=WAKEUP_RTC_OVERFLOW_EVENT_CLEAR (Reset the sticky WAKEUP_RTC_OVERFLOW_EVENT flag)
  [6] RTC_CLOCK_WAKEUP_CLEAR wo — Reset the sticky WAKEUP_RTC_CLOCK_EVENT flag
    1=WAKEUP_RTC_CLOCK_EVENT_CLEAR (Reset the sticky WAKEUP_RTC_CLOCK_EVENT flag)
  [5] RTC_ALARM_WAKEUP_CLEAR wo — Reset the sticky WAKEUP_RTC_ALARM_EVENT flag
    1=WAKEUP_RTC_ALARM_EVENT_CLEAR (Reset the sticky WAKEUP_RTC_ALARM_EVENT flag)
  [4] BB_TIMER_WAKEUP_CLEAR wo — Reset the sticky WAKEUP_BB_TIMER_EVENT flag
    1=WAKEUP_BB_TIMER_CLEAR (Reset the sticky WAKEUP_BB_TIMER_EVENT flag)
  [n] GPIO{n}_WAKEUP_CLEAR wo (n=0..3) — Reset the sticky WAKEUP_GPIO{n}_EVENT flag
    1=WAKEUP_GPIO{n}_EVENT_CLEAR (Reset the sticky WAKEUP_GPIO{n}_EVENT flag)
0x68 ACS_WAKEUP_CFG reset 0x40000 — Wake-up Configuration Register
  [18:16] DELAY — Delay from VDDD ready to digital clock enable (power of 2)
    0=WAKEUP_DELAY_1 (Wait for 1 32kHz clock cycle); 1=WAKEUP_DELAY_2 (Wait for 2 32kHz clock cycles); 2=WAKEUP_DELAY_4 (Wait for 4 32kHz clock cycles); 3=WAKEUP_DELAY_8 (Wait for 8 32kHz clock cycles); 4=WAKEUP_DELAY_16 (Wait for 16 32kHz clock cycles); 5=WAKEUP_DELAY_32 (Wait for 32 32kHz clock cycles); 6=WAKEUP_DELAY_64 (Wait for 64 32kHz clock cycles); 7=WAKEUP_DELAY_128 (Wait for 128 32kHz clock cycles)
  [11] DCDC_OVERLOAD_EN — Enable / Disable the Wake-up functionality on the DCDC overload flag
    0=WAKEUP_DCDC_OVERLOAD_DISABLE (Disable the wake-up functionality on the DCDC overload flag); 1=WAKEUP_DCDC_OVERLOAD_ENABLE (Enable the wake-up functionality on the DCDC overload flag)
  [9] FIFO_FULL_EN — Enable the wake-up on full FIFO
    0=WAKEUP_FIFO_DISABLE (Disable the wake-up functionality on the ULP data acquisition subsystem FIFO); 1=WAKEUP_FIFO_ENABLE (Enable the wake-up functionality on the ULP data acquisition subsystem FIFO)
  [8] RTC_OVERFLOW_EN — Enable / Disable the Wake-up functionality on RTC overflow flag
    0=WAKEUP_RTC_OVERFLOW_DISABLE (Disable the wake-up functionality on the RTC overflow flag); 1=WAKEUP_RTC_OVERFLOW_ENABLE (Enable the wake-up functionality on the RTC overflow flag)
  [n+4] GPIO{n}_POL (n=0..3) — Wake-up polarity on the GPIO{n} pad
    0=WAKEUP_GPIO{n}_RISING (Wake-up on the GPIO{n} rising edge); 1=WAKEUP_GPIO{n}_FALLING (Wake-up on the GPIO{n} falling edge)
  [n] GPIO{n}_EN (n=0..3) — Enable the wake-up functionality on the GPIO{n} pad
    0=WAKEUP_GPIO{n}_DISABLE (Disable the wake-up functionality on the GPIO{n} pad); 1=WAKEUP_GPIO{n}_ENABLE (Enable the wake-up functionality on the GPIO{n} pad)
0x6C ACS_WAKEUP_STATE ro — RTC Timer wake-up value and wakeup source
  [19:16] WAKEUP_SRC — Status register indicates the last wake-up source
    11=WAKEUP_DUE_TO_RTC_OVERFLOW (The last wake-up was due to the RTC Timer overflow); 10=WAKEUP_DUE_TO_RTC_CLOCK (The last wake-up was due to the RTC Timer clock); 9=WAKEUP_DUE_TO_RTC_ALARM (The last wake-up was due to the RTC Timer alarm); 8=WAKEUP_DUE_TO_THRESHOLD (The last wake-up was due to the ULP data acquisition subsystem threshold); 7=WAKEUP_DUE_TO_FIFO (The last wake-up was due to the ULP data acquisition subsystem FIFO); 6=WAKEUP_DUE_TO_ACOMP (The last wake-up was due to the Analog comparator); 5=WAKEUP_DUE_TO_DCDC_OVERLOAD (The last wake-up was due to the DCDC overload); 4=WAKEUP_DUE_TO_BB_TIMER (The last wake-up was due to the baseband timer alarm); {v}=WAKEUP_DUE_TO_GPIO{v} (The last wake-up was due to the GPIO{v} pad) (v=0..3)
  [7:0] RTC_VALUE — RTC counter value captured at wakeup event (only 8 LSBs, corresponds to 7.8 ms)
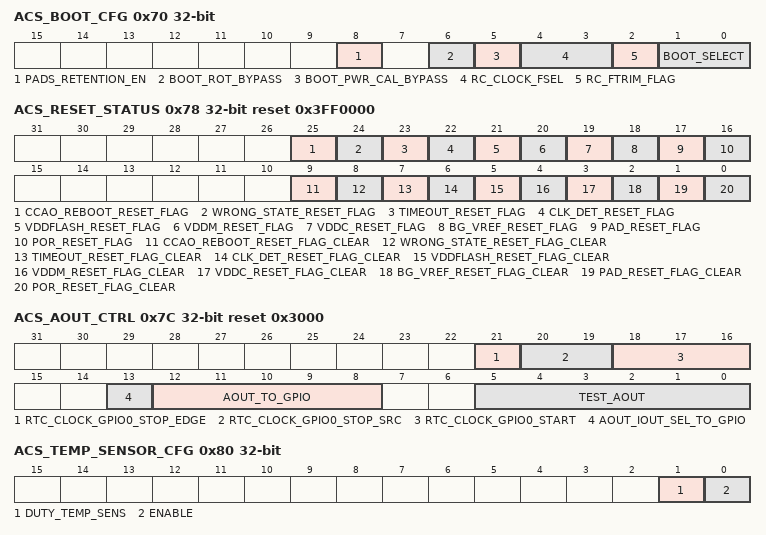
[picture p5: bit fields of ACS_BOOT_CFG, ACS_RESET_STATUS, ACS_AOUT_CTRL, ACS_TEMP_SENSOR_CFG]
0x70 ACS_BOOT_CFG — Boot configuration Register
  [8] PADS_RETENTION_EN — Enable / Disable the retention mode of the pads
    0=PADS_RETENTION_DISABLE (Disable the pad retention mode); 1=PADS_RETENTION_ENABLE (Enable the pad retention mode)
  [6] BOOT_ROT_BYPASS — Boot bypass execution of root of trust
    0=BOOT_ROT_BYPASS_DISABLE (ROM will execute RoT); 1=BOOT_ROT_BYPASS_ENABLE (ROM will not execute RoT)
  [5] BOOT_PWR_CAL_BYPASS — Boot bypass execution of system calibration
    0=BOOT_PWR_CAL_BYPASS_DISABLE (ROM will execute calibration of system); 1=BOOT_PWR_CAL_BYPASS_ENABLE (ROM will not execute calibration of system)
  [4:3] RC_CLOCK_FSEL ro — RC oscillator clock multiplier read only flag (mirror of CLOCK_MULT of ACS_RCOSC_CTRL register)
    0=RC_OSC_STATUS_3MHZ (The RC Oscillator is at 3 MHz); 1=RC_OSC_STATUS_12MHZ (The RC Oscillator is at 12 MHz); 2=RC_OSC_STATUS_24MHZ (The RC Oscillator is at 24 MHz); 3=RC_OSC_STATUS_48MHZ (The RC Oscillator is at 48 MHz)
  [2] RC_FTRIM_FLAG ro — RC oscillator trimming read only flag (mirror of FTRIM_FLAG of ACS_RCOSC_CTRL register
    0=RC_OSC_STATUS_UNCALIBRATED (The oscillators are not calibrated); 1=RC_OSC_STATUS_CALIBRATED (The oscillators are calibrated)
  [1:0] BOOT_SELECT — Boot selection to indicate boot source
    0=BOOT_FLASH_XTAL_DISABLE (The CM33 executes code from the flash and the XTAL will not be started at boot); 1=BOOT_CUSTOM (The CM33 executes code from the address specified in the wakeup information in retention RAM and the XTAL will not be started at boot); 2=BOOT_FLASH_XTAL_DEFAULT_TRIM (The CM33 executes code from the flash and the XTAL will be started at boot with the default trim); 3=BOOT_FLASH_XTAL_CUSTOM_TRIM (The CM33 executes code from the flash and the XTAL will be started at boot with trim from ACS_WAKEUP_GP_DATA)
0x74 ACS_BOOT_GP_DATA — Boot control Register Register
  [31:0] GP_DATA — 32-bit General-Purpose RW Data
0x78 ACS_RESET_STATUS reset 0x3FF0000 (reset mask 0x3FF0000) — ACS Reset Source Status Register
  [25] CCAO_REBOOT_RESET_FLAG ro — Sticky flag that detects that a CryptoCell Alway ON reboot reset occurred
    0=CCAO_REBOOT_RESET_FLAG_NOT_SET (The CryptoCell Always ON reboot reset has not triggered at least once); 1=CCAO_REBOOT_RESET_FLAG_SET (The CryptoCell Always ON reboot reset was triggered at least once since this status bit was last cleared)
  [24] WRONG_STATE_RESET_FLAG ro — Sticky flag that detects that a wrong state reset occurred
    0=WRONG_STATE_RESET_FLAG_NOT_SET (The wrong state reset has not triggered at least once); 1=WRONG_STATE_RESET_FLAG_SET (The wrong state reset was triggered at least once since this status bit was last cleared)
  [23] TIMEOUT_RESET_FLAG ro — Sticky flag that detects that a timeout in the power up sequence occurred
    0=TIMEOUT_RESET_FLAG_NOT_SET (The timeout reset has not triggered at least once); 1=TIMEOUT_RESET_FLAG_SET (The timeout reset was triggered at least once since this status bit was last cleared)
  [22] CLK_DET_RESET_FLAG ro — Sticky flag that detects that a clock detector reset occurred
    0=CLK_DET_RESET_FLAG_NOT_SET (The clock detector reset has not triggered at least once); 1=CLK_DET_RESET_FLAG_SET (The clock detector reset was triggered at least once since this status bit was last cleared)
  [21] VDDFLASH_RESET_FLAG ro — Sticky flag that detects that a VDDFLASH reset occurred (triggered by VDDFLASH_ready = 0)
    0=VDDFLASH_RESET_FLAG_NOT_SET (The VDDFLASH reset has not triggered at least once); 1=VDDFLASH_RESET_FLAG_SET (The VDDFLASH reset was triggered at least once since this status bit was last cleared)
  [20] VDDM_RESET_FLAG ro — Sticky flag that detects that a VDDM reset occurred (triggered by VDDM_ready = 0)
    0=VDDM_RESET_FLAG_NOT_SET (The VDDM reset has not triggered at least once); 1=VDDM_RESET_FLAG_SET (The VDDM reset was triggered at least once since this status bit was last cleared)
  [19] VDDC_RESET_FLAG ro — Sticky flag that detects that a VDDC reset occurred (triggered by VDDC_ready = 0)
    0=VDDC_RESET_FLAG_NOT_SET (The VDDC reset has not triggered at least once); 1=VDDC_RESET_FLAG_SET (The VDDC reset was triggered at least once since this status bit was last cleared)
  [18] BG_VREF_RESET_FLAG ro — Sticky flag that detects that a Bandagap reference voltage reset occurred
    0=BG_VREF_RESET_FLAG_NOT_SET (The band-gap reference voltage reset has not triggered at least once); 1=BG_VREF_RESET_FLAG_SET (The band-gap reference voltage was triggered at least once since this status bit was last cleared)
  [17] PAD_RESET_FLAG ro — Sticky flag that detects that a reset occurred due to pad NRESET
    0=PAD_RESET_FLAG_NOT_SET (The NRESET pad reset has not triggered at least once); 1=PAD_RESET_FLAG_SET (The NRESET pad reset was triggered at least once since this status bit was last cleared)
  [16] POR_RESET_FLAG ro — Sticky flag that detects that a POR reset occurred
    0=POR_RESET_FLAG_NOT_SET (The POR reset has not triggered at least once); 1=POR_RESET_FLAG_SET (The POR reset was triggered at least once since this status bit was last cleared)
  [9] CCAO_REBOOT_RESET_FLAG_CLEAR wo — Reset the sticky CCAO_REBOOT_RESET flag.
    1=CCAO_REBOOT_RESET_FLAG_CLEAR (Reset the sticky CCAO_REBOOT_RESET flag.)
  [8] WRONG_STATE_RESET_FLAG_CLEAR wo — Reset the sticky WRONG_STATE_RESET flag.
    1=WRONG_STATE_RESET_FLAG_CLEAR (Reset the sticky WRONG_STATE_RESET flag.)
  [7] TIMEOUT_RESET_FLAG_CLEAR wo — Reset the sticky TIMEOUT_RESET flag.
    1=TIMEOUT_RESET_FLAG_CLEAR (Reset the sticky TIMEOUT_RESET flag.)
  [6] CLK_DET_RESET_FLAG_CLEAR wo — Reset the sticky CLK_DET_RESET flag.
    1=CLK_DET_RESET_FLAG_CLEAR (Reset the sticky CLK_DET_RESET flag.)
  [5] VDDFLASH_RESET_FLAG_CLEAR wo — Reset the sticky VDDFLASH_RESET flag.
    1=VDDFLASH_RESET_FLAG_CLEAR (Reset the sticky VDDFLASH_RESET flag.)
  [4] VDDM_RESET_FLAG_CLEAR wo — Reset the sticky VDDM_RESET flag.
    1=VDDM_RESET_FLAG_CLEAR (Reset the sticky VDDM_RESET flag.)
  [3] VDDC_RESET_FLAG_CLEAR wo — Reset the sticky VDDC_RESET flag.
    1=VDDC_RESET_FLAG_CLEAR (Reset the sticky VDDC_RESET flag.)
  [2] BG_VREF_RESET_FLAG_CLEAR wo — Reset the sticky BG_VREF_RESET flag.
    1=BG_VREF_RESET_FLAG_CLEAR (Reset the sticky BG_VREF_RESET flag.)
  [1] PAD_RESET_FLAG_CLEAR wo — Reset the sticky PAD_RESET flag.
    1=PAD_RESET_FLAG_CLEAR (Reset the sticky PAD_RESET flag.)
  [0] POR_RESET_FLAG_CLEAR wo — Reset the sticky POR_RESET flag.
    1=POR_RESET_FLAG_CLEAR (Reset the sticky POR_RESET flag.)
0x7C ACS_AOUT_CTRL reset 0x3000 — Analog Output Configuration Register
  [21] RTC_CLOCK_GPIO0_STOP_EDGE — Stop edge for RTC clock output on AOUT
    0=GPIO0_RTC_CLK_STOP_RISING (Stop to output RTC clock on rising edge); 1=GPIO0_RTC_CLK_STOP_FALLING (Stop to output RTC clock on falling edge)
  [20:19] RTC_CLOCK_GPIO0_STOP_SRC — Stop source for RTC clock output on AOUT
    {v}=GPIO0_RTC_CLK_STOP_GPIO{v} (Stop to output RTC clock on GPIO{v} event) (v=0..3)
  [18:16] RTC_CLOCK_GPIO0_START — Start event for RTC clock output on AOUT (RTC prescaler and counter need to be enabled)
    0=GPIO0_RTC_CLK_DISABLE (No start event (GPIO0 not driven)); 1=GPIO0_RTC_CLK_125MS (Start to output RTC clock every 125 ms); 2=GPIO0_RTC_CLK_250MS (Start to output RTC clock every 250 ms); 3=GPIO0_RTC_CLK_500MS (Start to output RTC clock every 500 ms); 4=GPIO0_RTC_CLK_1S (Start to output RTC clock every 1 s); 5=GPIO0_RTC_CLK_2S (Start to output RTC clock every 2 s); 6=GPIO0_RTC_CLK_4S (Start to output RTC clock every 4 s); 7=GPIO0_RTC_CLK_8S (Start to output RTC clock every 8 s)
  [13] AOUT_IOUT_SEL_TO_GPIO — Selection between AOUT voltage or PTAT current source to GPIO
    0=SEL_IOUT_TO_GPIO (Select PTAT iref current source); 1=SEL_AOUT_TO_GPIO (Select AOUT voltage source)
  [12:8] AOUT_TO_GPIO — Select to which GPIO the AOUT voltage or PTAT current provided
    {v}=Select GPIO[{v}] as output (v=0..15); 16=AOUT_NOT_CONNECTED_TO_GPIO (None selected)
  [5:0] TEST_AOUT — AOUT test signal selection
    0=AOUT_VSSA (AOUT grounded); 1=AOUT_VCC (VCC); 2=AOUT_IPTAT (Band-gap ptat pmos current source); 3=AOUT_IVBE (Band-gap vbe ptat current source); 4=AOUT_IREF_1U (Band-gap 1uA pmos current source); 5=AOUT_IREF_50N (Band-gap 50nA pmos current source); 6=AOUT_IREF_10N (Band-gap 10nA nmos current source); 7=AOUT_VREG_BG (Band-gap regulated supply voltage / flash reference voltage); 8=AOUT_VREF_0P75V (Band-gap reference voltage 0p75V); 9=AOUT_VREF_0P75V_buf (Band-gap reference voltage 0p75V after internal buffer); 10=AOUT_VREF_0P67V (Band-gap reference voltage 0p67V); 11=AOUT_WEDAC (Band-gap WEDAC reference voltage); 12=AOUT_TEMP_SENSOR_VPTAT (Temperature sensor output voltage); 13=AOUT_NOT_USED (UNUSED Signal); 14=AOUT_LSAD_INTERNAL_VREF (LSAD internal vref); 15=AOUT_THERMISTOR_CURRENT (Thermistor current); 16=AOUT_IREF_1N_OUTPUT (PMU PTAT iref current source); 17=AOUT_VDDACS_OUTPUT (PMU vddacs voltage); 18=AOUT_RC_INTENAL_SUPPLY (RC intenal supply); 19=AOUT_RC32_INTENAL_SUPPLY (RC32 intenal supply); 20=AOUT_VDDA_SW (Vdda switch voltage); 21=AOUT_VDDSYN_SW (Vddsyn switch voltage); 22=AOUT_VDDRF_SW (Vddrf switch voltage); 23=AOUT_VDDT (VDDT switch voltage); 24=AOUT_VDDCCAO (VDDCCAO switch voltage); 25=AOUT_VDDSENSOR (VDDSENSOR switch voltage); 26=AOUT_VDDM (VDDM voltage output); 27=AOUT_VDDC (VDDC voltage output); 28=AOUT_VDDPA (VDDPA voltage output); 29=AOUT_VDDPA_ISENSE (VDDPA current sensing); 30=AOUT_FLASH0_TM0 (Instance Flash 0 TM0 connected to AOUT); 31=AOUT_VDDM_DRAM7_C (VDDM DRAM7 Core supply); 32=AOUT_VDDA (VDDA voltage output); 33=AOUT_VDDRF (VDDRF voltage output); 34=AOUT_VDDC_RF (VDDC RF power island supply); 35=AOUT_VDDFLASH (VDDFLASH voltage output); 36=AOUT_HIZ (HIZ (measure leakage)); 37=AOUT_RC32_IBP_12N_NTC (RC32 NTC current); 38=AOUT_VDDM_DRAM7_P (VDDM DRAM7 Peripheral supply); 39=AOUT_VDDC_CC (VDDC CryptoCell power island supply); 40=AOUT_VDDC_BB (VDDC Baseband power island supply); 41=DOUT_SP1 (Digital spare 1); 42=DOUT_SP2 (Digital spare 2); 43=DOUT_BG_READY (Band-gap ready signal); 44=DOUT_VDDRF_READY (vddrf ready signal); 45=DOUT_VDDC_READY (Vddc ready signal); 46=DOUT_VDDM_READY (Vddm ready signal); 47=DOUT_VDDCP_READY (vddcp ready signal); 48=DOUT_SP3 (Digital spare 3); 49=DOUT_VDDFLASH_READY (vddflash ready signal); 50=DOUT_CLK_PRESENT (Clock present from clock detector); 51=DOUT_XTAL_OK (Xtal ok); 52=DOUT_XTAL_CLK (Xtal clock); 53=DOUT_RC32_CLK (RC 32kHz clock); 54=DOUT_DCDC_ACTIVATED (DC-DC converter activated signal); 55=DOUT_DCDC_OVERLOAD (DC-DC converter overload signal); 56=DOUT_DCDC_VCC_READY (DC-DC converter vcc ready signal); 57=DOUT_SP4 (Digital spare 4); 58=DOUT_SP5 (Digital spare 5); 59=DOUT_SP6 (Digital spare 6); 60=DOUT_STANDBY_CLK (Standby clock); 61=DOUT_SAR_COMPARATOR (Comparator output of the SAR); 62=DOUT_CP_CLK (Charge Pump clock); 63=DOUT_ACOMP_OUT (Analog Comparator output signal)
0x80 ACS_TEMP_SENSOR_CFG — Temperature Sensor Configuration Register
  [1] DUTY_TEMP_SENS — Duty cycling temperature sensor
    0=LSAD_TEMP_SENS_NORMAL (Normal mode: temperature sensor enable only controlled by TEMP_SENS_ENABLE); 1=LSAD_TEMP_SENS_DUTY (Duty cycling temperature sensor (enabled only during LSAD conversion))
  [0] ENABLE — Internal temperature sensor enable
    0=TEMP_SENS_DISABLE (Disable the internal Temperature Sensor); 1=TEMP_SENS_ENABLE (Enable the internal Temperature Sensor)
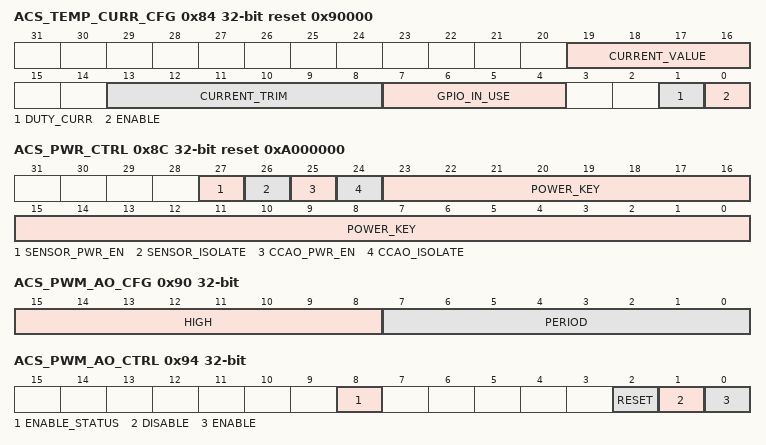
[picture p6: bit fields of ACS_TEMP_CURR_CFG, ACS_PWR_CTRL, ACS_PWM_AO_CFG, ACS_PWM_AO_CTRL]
0x84 ACS_TEMP_CURR_CFG reset 0x90000 — Source Current Configuration Register
  [19:16] CURRENT_VALUE — Temperature current value
    0=TEMP_CURR_1UA (Temperature current set to 1 uA); 9=TEMP_CURR_10UA (Temperature current set to 10 uA); 15=TEMP_CURR_16UA (Temperature current set to 16 uA)
  [13:8] CURRENT_TRIM — Temperature current trimming
    0=TEMP_CURR_TRIM_M32 (-10 percent trimming); 32=TEMP_CURR_TRIM_0 (Default trimming); 63=TEMP_CURR_TRIM_P31 (+10 percent trimming)
  [7:4] GPIO_IN_USE — GPIO from which the duty cycle is used
    {v}=TEMP_CURR_GPIO{v} (Duty cycle of GPIO{v} is used) (v=0..15)
  [1] DUTY_CURR — Duty cycling current enable
    0=LSAD_CURR_NORMAL (Normal mode: current enable only controlled by CURR_ENABLE); 1=LSAD_CURR_DUTY (Duty cycling current enable (enabled only during LSAD conversion))
  [0] ENABLE — Temperature current enable
    0=TEMP_CURR_DISABLE (Disable the temperature current); 1=TEMP_CURR_ENABLE (Enable the temperature current)
0x88 ACS_GP_DATA — JIC RW Register
  [31:0] GP_DATA — 32-bit General-Purpose RW Data
0x8C ACS_PWR_CTRL reset 0xA000000 (reset mask 0xF000000) — ACS Power Control Register
  [27] SENSOR_PWR_EN — Sensor power control
    0=ACS_SENSOR_SHUTDOWN (Sensor is powered off); 1=ACS_SENSOR_POWERED (Sensor is powered on)
  [26] SENSOR_ISOLATE — Sensor isolation control
    0=ACS_SENSOR_NOT_ISOLATE (Sensor is not isolate); 1=ACS_SENSOR_ISOLATE (Sensor is isolate)
  [25] CCAO_PWR_EN — CryptoCell always on power control
    0=ACS_CCAO_SHUTDOWN (CryptoCell Always on is powered off); 1=ACS_CCAO_POWERED (CryptoCell Always on is powered on)
  [24] CCAO_ISOLATE — CryptoCell always on isolation control
    0=ACS_CCAO_NOT_ISOLATE (CryptoCell Always on is not isolate); 1=ACS_CCAO_ISOLATE (CryptoCell Always on is isolate)
  [23:0] POWER_KEY wo — Write a key to enable the write to power controls
    0x63412B=ACS_PWR_KEY (Write 24-bit key to enable the write access to power controls)
0x90 ACS_PWM_AO_CFG — ACS PWM Always-On Configuration Register
  [15:8] HIGH — PWM high duty cycle
  [7:0] PERIOD — PWM period
0x94 ACS_PWM_AO_CTRL (reset mask 0x100) — ACS PWM Always-On Control Register
  [8] ENABLE_STATUS ro — Status of the PWM enable
    0=PWM_IS_DISABLED; 1=PWM_IS_ENABLED
  [2] RESET wo — Reset the PWM
    1=PWM_RESET (Reset PWM)
  [1] DISABLE wo — Disable the PWM
    1=PWM_DISABLE (Disable PWM)
  [0] ENABLE wo — Enable the PWM
    1=PWM_ENABLE (Enable PWM)
0x98 ACS_PWM_AO_COUNT ro — ACS PWM Always-On counter
  [7:0] COUNTER — PWM counter
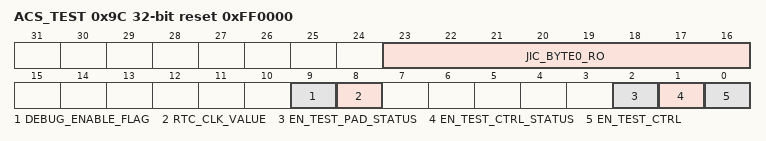
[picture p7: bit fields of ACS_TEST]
0x9C ACS_TEST reset 0xFF0000 (reset mask 0xFF0306) — EN_TEST control and others status
  [23:16] JIC_BYTE0_RO ro — JIC read only register bits (returning signals from analog part: tied to 1)
  [9] DEBUG_ENABLE_FLAG ro — Status flag of debug enable
    0=DEBUG_DISABLE (Debug is enable); 1=DEBUG_ENABLE (Debug is disable)
  [8] RTC_CLK_VALUE ro — Value of RTC clock
  [2] EN_TEST_PAD_STATUS ro — EN_TEST pad state
    0=EN_TEST_PAD_LOW (EN_TEST pad is low.); 1=EN_TEST_PAD_HIGH (EN_TEST pad is high.)
  [1] EN_TEST_CTRL_STATUS ro — EN_TEST_CTRL state
    0=EN_TEST_CTRL_LOW (EN_TEST_CTRL is low.); 1=EN_TEST_CTRL_HIGH (EN_TEST_CTRL is high.)
  [0] EN_TEST_CTRL wo — EN_TEST_CTRL can be written only one time
    0=DISABLE_EN_TEST_CTRL; 1=ENABLE_EN_TEST_CTRL
